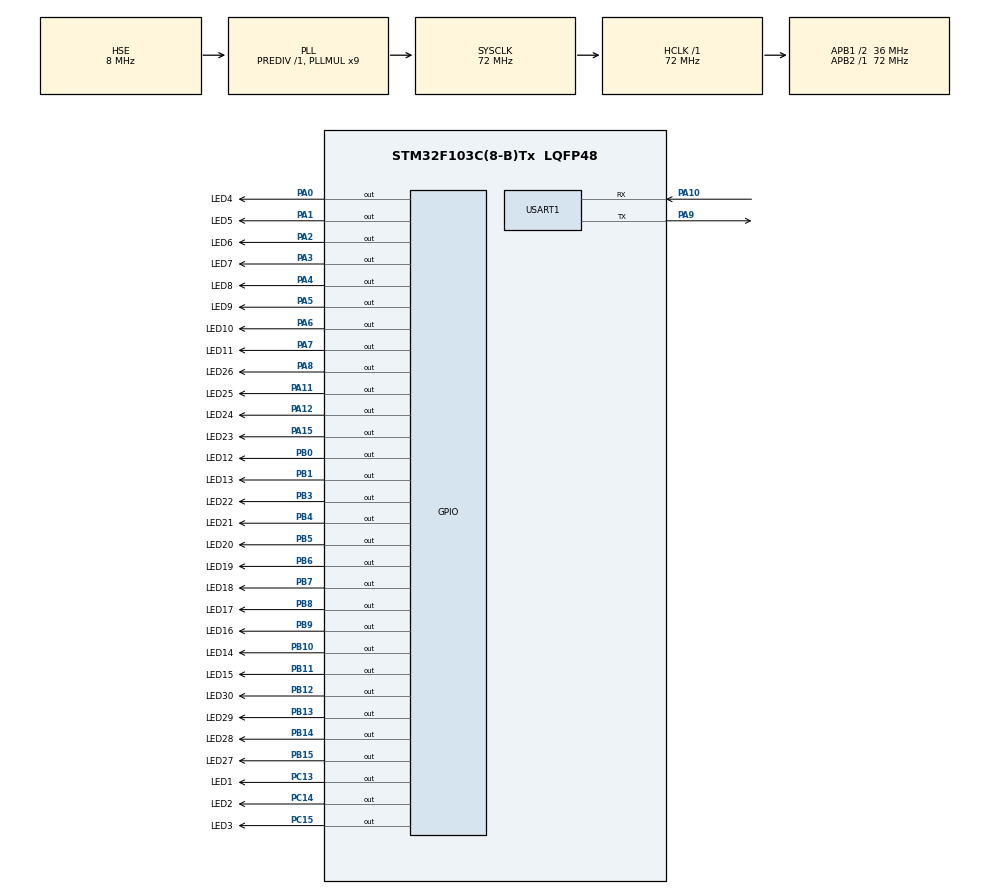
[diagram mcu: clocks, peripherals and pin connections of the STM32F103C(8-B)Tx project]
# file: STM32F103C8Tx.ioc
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Mcu.Family=STM32F1
Mcu.Name=STM32F103C(8-B)Tx
Mcu.Package=LQFP48
NVIC.PriorityGroup=NVIC_PRIORITYGROUP_4
NVIC.TIM2_IRQn=true\:0\:0\:false\:false\:true\:true\:true\:true
NVIC.USART1_IRQn=true\:0\:0\:false\:false\:true\:true\:true\:true
PA0-WKUP.GPIO_Label=LED4
PA0-WKUP.PinState=GPIO_PIN_SET
PA0-WKUP.Signal=GPIO_Output
PA1.GPIO_Label=LED5
PA1.PinState=GPIO_PIN_SET
PA1.Signal=GPIO_Output
PA10.Mode=Asynchronous
PA10.Signal=USART1_RX
PA11.GPIO_Label=LED25
PA11.PinState=GPIO_PIN_SET
PA11.Signal=GPIO_Output
PA12.GPIO_Label=LED24
PA12.PinState=GPIO_PIN_SET
PA12.Signal=GPIO_Output
PA13.Mode=Serial_Wire
PA13.Signal=SYS_JTMS-SWDIO
PA14.Mode=Serial_Wire
PA14.Signal=SYS_JTCK-SWCLK
PA15.GPIO_Label=LED23
PA15.PinState=GPIO_PIN_SET
PA15.Signal=GPIO_Output
PA2.GPIO_Label=LED6
PA2.PinState=GPIO_PIN_SET
PA2.Signal=GPIO_Output
PA3.GPIO_Label=LED7
PA3.PinState=GPIO_PIN_SET
PA3.Signal=GPIO_Output
PA4.GPIO_Label=LED8
PA4.PinState=GPIO_PIN_SET
PA4.Signal=GPIO_Output
PA5.GPIO_Label=LED9
PA5.PinState=GPIO_PIN_SET
PA5.Signal=GPIO_Output
PA6.GPIO_Label=LED10
PA6.PinState=GPIO_PIN_SET
PA6.Signal=GPIO_Output
PA7.GPIO_Label=LED11
PA7.PinState=GPIO_PIN_SET
PA7.Signal=GPIO_Output
PA8.GPIO_Label=LED26
PA8.PinState=GPIO_PIN_SET
PA8.Signal=GPIO_Output
PA9.Mode=Asynchronous
PA9.Signal=USART1_TX
PB0.GPIO_Label=LED12
PB0.PinState=GPIO_PIN_SET
PB0.Signal=GPIO_Output
PB1.GPIO_Label=LED13
PB1.PinState=GPIO_PIN_SET
PB1.Signal=GPIO_Output
PB10.GPIO_Label=LED14
PB10.PinState=GPIO_PIN_SET
PB10.Signal=GPIO_Output
PB11.GPIO_Label=LED15
PB11.PinState=GPIO_PIN_SET
PB11.Signal=GPIO_Output
PB12.GPIO_Label=LED30
PB12.PinState=GPIO_PIN_SET
PB12.Signal=GPIO_Output
PB13.GPIO_Label=LED29
PB13.PinState=GPIO_PIN_SET
PB13.Signal=GPIO_Output
PB14.GPIO_Label=LED28
PB14.PinState=GPIO_PIN_SET
PB14.Signal=GPIO_Output
PB15.GPIO_Label=LED27
PB15.PinState=GPIO_PIN_SET
PB15.Signal=GPIO_Output
PB3.GPIO_Label=LED22
PB3.PinState=GPIO_PIN_SET
PB3.Signal=GPIO_Output
PB4.GPIO_Label=LED21
PB4.PinState=GPIO_PIN_SET
PB4.Signal=GPIO_Output
PB5.GPIO_Label=LED20
PB5.PinState=GPIO_PIN_SET
PB5.Signal=GPIO_Output
PB6.GPIO_Label=LED19
PB6.PinState=GPIO_PIN_SET
PB6.Signal=GPIO_Output
PB7.GPIO_Label=LED18
PB7.PinState=GPIO_PIN_SET
PB7.Signal=GPIO_Output
PB8.GPIO_Label=LED17
PB8.PinState=GPIO_PIN_SET
PB8.Signal=GPIO_Output
PB9.GPIO_Label=LED16
PB9.PinState=GPIO_PIN_SET
PB9.Signal=GPIO_Output
PC13-TAMPER-RTC.GPIO_Label=LED1
PC13-TAMPER-RTC.PinState=GPIO_PIN_SET
PC13-TAMPER-RTC.Signal=GPIO_Output
PC14-OSC32_IN.GPIO_Label=LED2
PC14-OSC32_IN.PinState=GPIO_PIN_SET
PC14-OSC32_IN.Signal=GPIO_Output
PC15-OSC32_OUT.GPIO_Label=LED3
PC15-OSC32_OUT.PinState=GPIO_PIN_SET
PC15-OSC32_OUT.Signal=GPIO_Output
PD0-OSC_IN.Mode=HSE-External-Oscillator
PD0-OSC_IN.Signal=RCC_OSC_IN
PD1-OSC_OUT.Mode=HSE-External-Oscillator
PD1-OSC_OUT.Signal=RCC_OSC_OUT
ProjectManager.HeapSize=0x200
ProjectManager.StackSize=0x400
ProjectManager.TargetToolchain=MDK-ARM V5.32
RCC.AHBFreq_Value=72000000
RCC.APB1CLKDivider=RCC_HCLK_DIV2
RCC.APB1Freq_Value=36000000
RCC.APB1TimFreq_Value=72000000
RCC.APB2Freq_Value=72000000
RCC.APB2TimFreq_Value=72000000
RCC.HCLKFreq_Value=72000000
RCC.PLLMUL=RCC_PLL_MUL9
RCC.PLLSourceVirtual=RCC_PLLSOURCE_HSE
RCC.SYSCLKFreq_VALUE=72000000
RCC.SYSCLKSource=RCC_SYSCLKSOURCE_PLLCLK
RCC.USBFreq_Value=72000000
TIM2.Period=50-1
TIM2.Prescaler=72-1
USART1.VirtualMode=VM_ASYNC
VP_TIM2_VS_ClockSourceINT.Mode=Internal
board=custom

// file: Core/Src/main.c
/* USER CODE BEGIN Header */
/**
  ******************************************************************************
  * @file           : main.c
  * @brief          : Main program body
  ******************************************************************************
  * @attention
  *
  * Copyright (c) 2026 STMicroelectronics.
  * All rights reserved.
  *
  * This software is licensed under terms that can be found in the LICENSE file
  * in the root directory of this software component.
  * If no LICENSE file comes with this software, it is provided AS-IS.
  *
  ******************************************************************************
  */
/* USER CODE END Header */
#include "main.h"
#include "tim.h"
#include "usart.h"
#include "gpio.h"

/* USER CODE BEGIN Includes */
#include "app.h"

#include <stdio.h>
#include <string.h>
/* USER CODE END Includes */

void SystemClock_Config(void);

int main(void)
{

  /* MCU Configuration--------------------------------------------------------*/

  /* Reset of all peripherals, Initializes the Flash interface and the Systick. */
  HAL_Init();

  /* Configure the system clock */
  SystemClock_Config();

  /* Initialize all configured peripherals */
  MX_GPIO_Init();
  MX_USART1_UART_Init();
  MX_TIM2_Init();
  /* USER CODE BEGIN 2 */
  App_Init();
  /* USER CODE END 2 */

  /* Infinite loop */
  while (1)
  {

    /* USER CODE BEGIN 3 */

    App_Loop();

  }
  /* USER CODE END 3 */
}

void SystemClock_Config(void)
{
  RCC_OscInitTypeDef RCC_OscInitStruct = {0};
  RCC_ClkInitTypeDef RCC_ClkInitStruct = {0};

  /** Initializes the RCC Oscillators according to the specified parameters
  * in the RCC_OscInitTypeDef structure.
  */
  RCC_OscInitStruct.OscillatorType = RCC_OSCILLATORTYPE_HSE;
  RCC_OscInitStruct.HSEState = RCC_HSE_ON;
  RCC_OscInitStruct.HSEPredivValue = RCC_HSE_PREDIV_DIV1;
  RCC_OscInitStruct.HSIState = RCC_HSI_ON;
  RCC_OscInitStruct.PLL.PLLState = RCC_PLL_ON;
  RCC_OscInitStruct.PLL.PLLSource = RCC_PLLSOURCE_HSE;
  RCC_OscInitStruct.PLL.PLLMUL = RCC_PLL_MUL9;
  if (HAL_RCC_OscConfig(&RCC_OscInitStruct) != HAL_OK)
  {
    Error_Handler();
  }

  /** Initializes the CPU, AHB and APB buses clocks
  */
  RCC_ClkInitStruct.ClockType = RCC_CLOCKTYPE_HCLK|RCC_CLOCKTYPE_SYSCLK
                              |RCC_CLOCKTYPE_PCLK1|RCC_CLOCKTYPE_PCLK2;
  RCC_ClkInitStruct.SYSCLKSource = RCC_SYSCLKSOURCE_PLLCLK;
  RCC_ClkInitStruct.AHBCLKDivider = RCC_SYSCLK_DIV1;
  RCC_ClkInitStruct.APB1CLKDivider = RCC_HCLK_DIV2;
  RCC_ClkInitStruct.APB2CLKDivider = RCC_HCLK_DIV1;

  if (HAL_RCC_ClockConfig(&RCC_ClkInitStruct, FLASH_LATENCY_2) != HAL_OK)
  {
    Error_Handler();
  }
}

void Error_Handler(void)
{
  __disable_irq();
  while (1)
  {
  }
}
